# CY8C5868LTI_LP039 register map
File version: 0.1
CY8C58LP
Registers are 8-bit, read-write, no defined reset value unless marked. A register's access mark holds for its fields unless they carry their own. Offsets are from the block's base; lines under a group give offsets from that group; [hi:lo] are bit positions; {n}, {i} and the like mark numbered series; 'fields as' and 'values as' point back to an identical list; <NAME> marks a mode.

## Memory map
0x00000000 I2C
0x00000000 deltaTimer
0x00000000 gpsSerial — UART
0x00000000 xbeeSerial — UART
0x00000000 debugSerial — UART

## deltaTimer
Base 0x00000000
0x40006504 deltaTimer_COUNTER 32-bit — UDB.A0 - Current Down Counter Value
0x40006524 deltaTimer_PERIOD 32-bit — UDB.D0 - Assigned Period
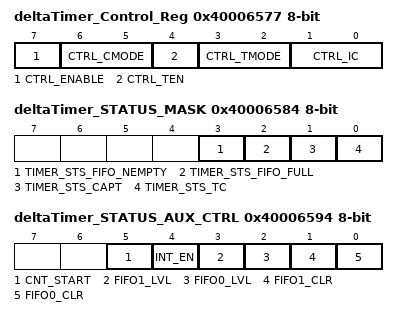
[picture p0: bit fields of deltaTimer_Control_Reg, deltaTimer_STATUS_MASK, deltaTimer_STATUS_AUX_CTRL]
0x40006577 deltaTimer_Control_Reg — UDB Control Register - Assigned Control Register Value
  [7] CTRL_ENABLE — Enable the Timer
  [6:5] CTRL_CMODE — Capture Mode
  [4] CTRL_TEN — Trigger Enable Bit
  [3:2] CTRL_TMODE — Trigger Mode
  [1:0] CTRL_IC — Interrupt Count
0x40006584 deltaTimer_STATUS_MASK — UDB Status bits Interrupt Mask Enable Register
  [3] TIMER_STS_FIFO_NEMPTY ro — FIFO Empty status
  [2] TIMER_STS_FIFO_FULL ro — FIFO Full Status
  [1] TIMER_STS_CAPT ro — Enables the Interrupt on Capture
  [0] TIMER_STS_TC ro — Enables the Interrupt on TC
0x40006594 deltaTimer_STATUS_AUX_CTRL — UDB Auxilliary Control Register
  [5] CNT_START — FIFO0 clear
    0=E_CNT_START0 (Disable counter); 1=E_CNT_START1 (Enable counter)
  [4] INT_EN
    0=E_INT_EN0 (Interrupt disabled); 1=E_INT_EN1 (Interrupt enabled)
  [3] FIFO1_LVL — FIFO level
    0=E_FIFO_LVL_0 (FIFO LVL: input mode: FIFO not full; output mode: FIFO not empty); 1=E_FIFO_LVL_1 (FIFO LVL: input mode: FIFO at least 1/2 empty; output mode: FIFO at least 1/2 full)
  [2] FIFO0_LVL — FIFO level
    values as FIFO1_LVL
  [1] FIFO1_CLR — FIFO1 clear
    0=E_FIFO_CLR_0 (Normal FIFO operation); 1=E_FIFO_CLR_1 (Clear FIFO state)
  [0] FIFO0_CLR — FIFO0 clear
    values as FIFO1_CLR

## gpsSerial — UART
Base 0x00000000
0x40006422 RX_gpsSerial_RX_ADDRESS1 — RX Address1 Register
0x40006432 RX_gpsSerial_RX_ADDRESS2 — RX Address2 Register
0x40006442 RX_gpsSerial_RX_DATA — RX Data Register
0x40006444 TX_gpsSerial_TX_DATA — TX Data Register
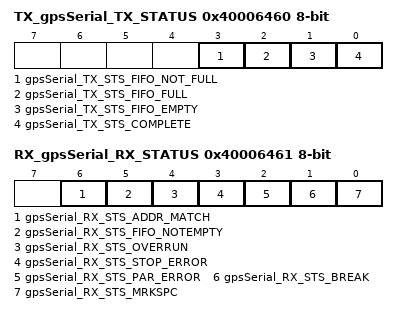
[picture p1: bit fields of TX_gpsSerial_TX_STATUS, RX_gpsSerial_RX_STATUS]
0x40006460 TX_gpsSerial_TX_STATUS — TX status register
  [3] gpsSerial_TX_STS_FIFO_NOT_FULL ro, [2] gpsSerial_TX_STS_FIFO_FULL ro, [1] gpsSerial_TX_STS_FIFO_EMPTY ro, [0] gpsSerial_TX_STS_COMPLETE ro
0x40006461 RX_gpsSerial_RX_STATUS — RX status register
  [6] gpsSerial_RX_STS_ADDR_MATCH ro, [5] gpsSerial_RX_STS_FIFO_NOTEMPTY ro, [4] gpsSerial_RX_STS_OVERRUN ro, [3] gpsSerial_RX_STS_STOP_ERROR ro, [2] gpsSerial_RX_STS_PAR_ERROR ro, [1] gpsSerial_RX_STS_BREAK ro, [0] gpsSerial_RX_STS_MRKSPC ro

## xbeeSerial — UART
Base 0x00000000
0x40006443 TX_xbeeSerial_TX_DATA — TX Data Register
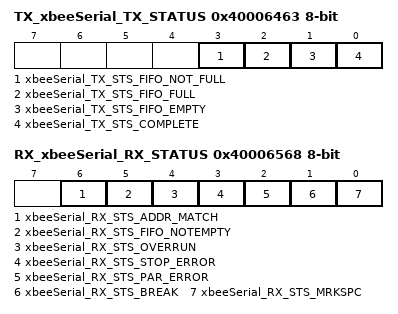
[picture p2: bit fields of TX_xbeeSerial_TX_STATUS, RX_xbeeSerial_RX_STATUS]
0x40006463 TX_xbeeSerial_TX_STATUS — TX status register
  [3] xbeeSerial_TX_STS_FIFO_NOT_FULL ro, [2] xbeeSerial_TX_STS_FIFO_FULL ro, [1] xbeeSerial_TX_STS_FIFO_EMPTY ro, [0] xbeeSerial_TX_STS_COMPLETE ro
0x4000652B RX_xbeeSerial_RX_ADDRESS1 — RX Address1 Register
0x4000653B RX_xbeeSerial_RX_ADDRESS2 — RX Address2 Register
0x4000654B RX_xbeeSerial_RX_DATA — RX Data Register
0x40006568 RX_xbeeSerial_RX_STATUS — RX status register
  [6] xbeeSerial_RX_STS_ADDR_MATCH ro, [5] xbeeSerial_RX_STS_FIFO_NOTEMPTY ro, [4] xbeeSerial_RX_STS_OVERRUN ro, [3] xbeeSerial_RX_STS_STOP_ERROR ro, [2] xbeeSerial_RX_STS_PAR_ERROR ro, [1] xbeeSerial_RX_STS_BREAK ro, [0] xbeeSerial_RX_STS_MRKSPC ro

## debugSerial — UART
Base 0x00000000
0x40006426 RX_debugSerial_RX_ADDRESS1 — RX Address1 Register
0x40006436 RX_debugSerial_RX_ADDRESS2 — RX Address2 Register
0x40006446 RX_debugSerial_RX_DATA — RX Data Register
0x40006449 TX_debugSerial_TX_DATA — TX Data Register
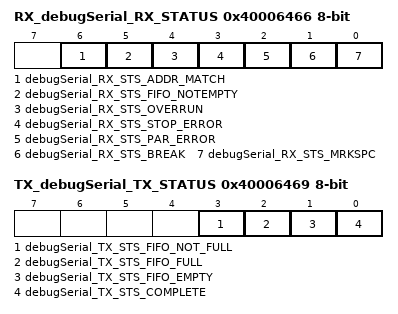
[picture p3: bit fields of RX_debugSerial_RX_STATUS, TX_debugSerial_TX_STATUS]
0x40006466 RX_debugSerial_RX_STATUS — RX status register
  [6] debugSerial_RX_STS_ADDR_MATCH ro, [5] debugSerial_RX_STS_FIFO_NOTEMPTY ro, [4] debugSerial_RX_STS_OVERRUN ro, [3] debugSerial_RX_STS_STOP_ERROR ro, [2] debugSerial_RX_STS_PAR_ERROR ro, [1] debugSerial_RX_STS_BREAK ro, [0] debugSerial_RX_STS_MRKSPC ro
0x40006469 TX_debugSerial_TX_STATUS — TX status register
  [3] debugSerial_TX_STS_FIFO_NOT_FULL ro, [2] debugSerial_TX_STS_FIFO_FULL ro, [1] debugSerial_TX_STS_FIFO_EMPTY ro, [0] debugSerial_TX_STS_COMPLETE ro
